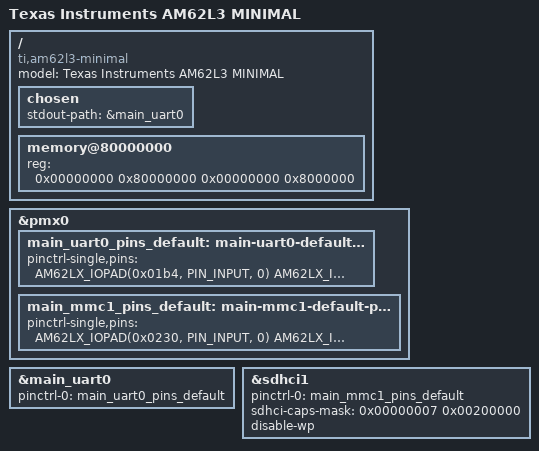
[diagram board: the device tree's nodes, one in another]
// SPDX-License-Identifier: GPL-2.0-only or MIT
/*
 * AM62L3 Minimal
 *
 * DT supports loading U-Boot binaries via UART and kernel image,
 * initramfs, and kernel devicetree through SD.
 *
 * Technical Reference Manual: https://www.ti.com/lit/pdf/sprujb4
 */

/dts-v1/;

#include "k3-am62l3.dtsi"

/ {
	compatible = "ti,am62l3-minimal", "ti,am62l3";
	model = "Texas Instruments AM62L3 MINIMAL";

	chosen {
		stdout-path = &main_uart0;
	};

	memory@80000000 {
		/* Limited to 128MB */
		reg = <0x00000000 0x80000000 0x00000000 0x8000000>;
		device_type = "memory";
		bootph-all;
	};
};

&pmx0 {
	main_uart0_pins_default: main-uart0-default-pins {
		pinctrl-single,pins = <
			AM62LX_IOPAD(0x01b4, PIN_INPUT, 0)	/* (D13) UART0_RXD */
			AM62LX_IOPAD(0x01b8, PIN_OUTPUT, 0)	/* (C13) UART0_TXD */
		>;
		bootph-all;
	};

	main_mmc1_pins_default: main-mmc1-default-pins {
		pinctrl-single,pins = <
			AM62LX_IOPAD(0x0230, PIN_INPUT, 0) /* (Y3) MMC1_CMD */
			AM62LX_IOPAD(0x0228, PIN_OUTPUT, 0) /* (Y2) MMC1_CLK */
			AM62LX_IOPAD(0x0224, PIN_INPUT, 0) /* (AA1) MMC1_DAT0 */
			AM62LX_IOPAD(0x0220, PIN_INPUT, 0) /* (Y4) MMC1_DAT1 */
			AM62LX_IOPAD(0x021c, PIN_INPUT, 0) /* (AA2) MMC1_DAT2 */
			AM62LX_IOPAD(0x0218, PIN_INPUT, 0) /* (AB2) MMC1_DAT3 */
			AM62LX_IOPAD(0x0234, PIN_INPUT, 0) /* (B6) MMC1_SDCD */
		>;
		bootph-all;
	};
};

&main_uart0 {
	pinctrl-names = "default";
	pinctrl-0 = <&main_uart0_pins_default>;
	bootph-all;
	status = "okay";
};

&sdhci1 {
	/* SD/MMC */
	pinctrl-names = "default";
	pinctrl-0 = <&main_mmc1_pins_default>;
	/* Limited to legacy mode */
	sdhci-caps-mask = <0x00000007 0x00200000>;
	disable-wp;
	bootph-all;
	status = "okay";
};
